# psoc4hvms128k register map
Vendor: Infineon Technologies; Series: PSOC4HVMS128K; File version: 1.0
CPU: CM0PLUS r0p1, little endian, MPU, no FPU, VTOR, 2 interrupt priority bits, 31 interrupts
Registers are 32-bit, read-write, reset 0x0 unless marked. A register's access mark holds for its fields unless they carry their own. Offsets are from the block's base; [hi:lo] are bit positions; {n}, {i} and the like mark numbered series; 'fields as' and 'values as' point back to an identical list; <NAME> marks a mode.

## SAR0 — SAR ADC with Sequencer
Base 0x403A0000
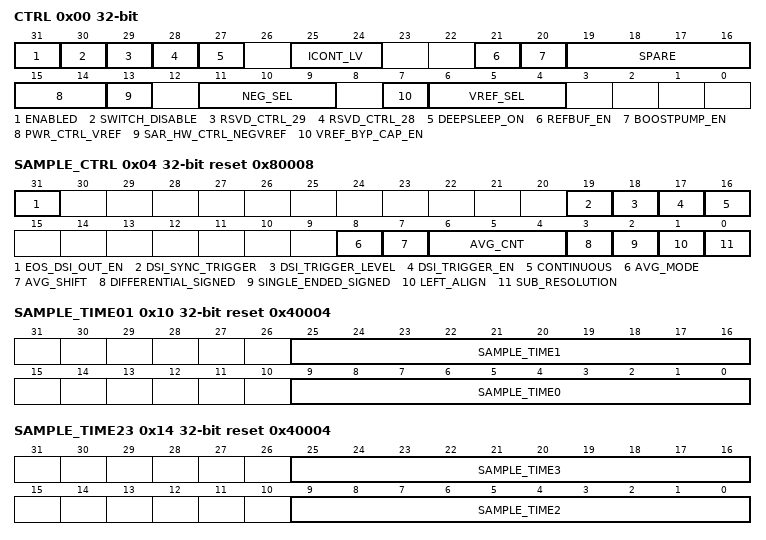
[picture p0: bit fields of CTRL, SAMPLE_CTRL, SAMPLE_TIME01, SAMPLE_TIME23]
0x00 CTRL — Analog control register.
  [31] ENABLED — - 0: SAR IP disabled (put analog in power down and stop clocks), also can clear FW_TRIGGER and INJ_START_EN (if not tailgaiting) on write. - 1: SAR IP enabled.
  [30] SWITCH_DISABLE — Disable SAR sequencer from enabling routing switches (note DSI and firmware can always close switches independent of this control) - 0: Normal mode, SAR sequencer changes switches according to pin address in channel configurations - 1: Switches disabled, SAR sequencer does not enable any switches, it is the responsibility of the firmware or UDBs (through DSI) to set the switches to route the signal to be converted through the SARMUX
  [29] RSVD_CTRL_29
  [28] RSVD_CTRL_28
  [27] DEEPSLEEP_ON — - 0: SARMUX IP disabled off during DeepSleep power mode - 1: SARMUX IP remains enabled during DeepSleep power mode (if ENABLED=1)
  [25:24] ICONT_LV — SARADC low power mode.
    0=NORMAL_PWR (normal power (default), max clk_sar is 18MHz.); 1=HALF_PWR (1/2 power mode, max clk_sar is 9MHz.); 2=MORE_PWR (1.333 power mode, max clk_sar is 18MHz.); 3=QUARTER_PWR (1/4 power mode, max clk_sar is 4.5MHz.)
  [21] REFBUF_EN — 1 - Enable the SARREFBUF. This bit needs to be set when SAR is enabled and needs reference buffer.
  [20] BOOSTPUMP_EN — SARADC internal pump: 0=disabled: pump output is VDDA, 1=enabled: pump output is boosted.
  [19:16] SPARE — Spare controls, not yet designated, for late changes done with an ECO
  [15:14] PWR_CTRL_VREF — VREF buffer low power mode.
    0=NORMAL_PWR (normal power (default), bypass cap, max clk_sar is 18MHz.); 1=HALF_PWR (deprecated); 2=THIRD_PWR (Invalid for PSoC4A, otherwise 2X power, no bypass cap, max clk_sar is 1.8MHz); 3=QUARTER_PWR (deprecated)
  [13] SAR_HW_CTRL_NEGVREF — Hardware control: 0=only firmware control, 1=hardware control masked by firmware setting for VREF to NEG switch.
  [11:9] NEG_SEL — SARADC internal NEG selection for Single ended conversion
    0=VSSA_KELVIN (NEG input of SARADC is connected to 'vssa_kelvin', gives more precision around zero. Note this opens both SARADC internal switches, therefore use this value to insert a break-before-make cycle on those switches when SWITCH_DISABLE is high.); 1=ART_VSSA (NEG input of SARADC is connected to VSSA in AROUTE close to the SARADC); 2=P1 (NEG input of SARADC is connected to P1 pin of SARMUX); 3=P3 (NEG input of SARADC is connected to P3 pin of SARMUX); 4=P5 (NEG input of SARADC is connected to P5 pin of SARMUX); 5=P7 (NEG input of SARADC is connected to P7 pin of SARMUX); 6=ACORE (NEG input of SARADC is connected to an ACORE in AROUTE); 7=VREF (NEG input of SARADC is shorted with VREF input of SARADC.)
  [7] VREF_BYP_CAP_EN — VREF bypass cap enable for when VREF buffer is on
  [6:4] VREF_SEL — SARADC internal VREF selection.
    0=RSVD_VREF_0 (N/A); 1=RSVD_VREF_1 (N/A); 2=RSVD_VREF_2 (N/A); 3=VREF_ADFT (Test mode only); 4=VBGR (1.2V from SRSS BandGap (VREF buffer on)); 5=VREF_EXT (External precision Vref direct from a pin (low impedance path).); 6=VDDA_DIV_2 (Vdda/2 (VREF buffer on)); 7=VDDA
0x04 SAMPLE_CTRL reset 0x80008 — Sample control register.
  [31] EOS_DSI_OUT_EN — Enable to output EOS_INTR to DSI. When enabled each time EOS_INTR is set by the hardware also a pulse is send on the dsi_eos signal.
  [19] DSI_SYNC_TRIGGER — - 0: bypass clock domain synchronisation of the DSI trigger signal. - 1: synchronize the DSI trigger signal to the SAR clock domain, if needed an edge detect is done in the peripheral clock domain.
  [18] DSI_TRIGGER_LEVEL — - 0: DSI trigger signal is a pulse input, a positive edge detected on the DSI trigger signal triggers a new scan. - 1: DSI trigger signal is a level input, as long as the DSI trigger signal remains high the SAR will do continuous scans.
  [17] DSI_TRIGGER_EN — - 0: firmware trigger only: disable hardware (DSI) trigger. - 1: enable hardware (DSI) trigger (e.g. from TCPWM, GPIO or UDB).
  [16] CONTINUOUS — - 0: Wait for next FW_TRIGGER (one shot) or hardware (DSI) trigger (e.g. from TPWM for periodic triggering) before scanning enabled channels. - 1: Continuously scan enabled channels, ignore triggers.
  [8] AVG_MODE — Averaging mode, in DSI mode this bit is ignored and only AccuNDump mode is available.
    0=ACCUNDUMP (Accumulate and Dump (1st order accumulate and dump filter): a channel will be sampled back to back and averaged); 1=INTERLEAVED (Interleaved: On each scan (trigger) one sample is taken per channel and averaged over several scans. NOTE: If all channels in a scan are configured for interleaved averaging, then EOS is only asserted after the last scan of the average count. In addition, a new trigger which would cause a collision, will be ignored, except for the last scan of the average count. If the collision is detected in the the last scan, the trigger will be pended and will be executed after the last scan is completed.)
  [7] AVG_SHIFT — Averaging shifting: after averaging the result is shifted right to fit in the sample resolution. For averaging the sample resolution is the highest resolution allowed by wounding.
  [6:4] AVG_CNT — Averaging Count for channels that have averaging enabled (AVG_EN). A channel will be sampled (1<<(AVG_CNT+1)) = [2..256] times. - In ACCUNDUMP mode (1st order accumulate and dump filter) a channel will be sampled back to back, the average result is calculated and stored and then the next enabled channel is sampled. If shifting is not enabled (AVG_SHIFT=0) then the result is forced to shift right so that is fits in 16 bits, so right shift is done by max(0,AVG_CNT-3). - In INTERLEAVED mode one sample is taken per triggered scan, only in the scan where the final averaging count is reached a valid average is calculated and stored in the RESULT register (by definition the same scan for all the channels that have averaging enabled). In all other scans the RESULT register for averaged channels will have an invalid result and the intermediate accumulated value is stored in the 16-bit WORK register. In this mode make sure that the averaging count is low enough to ensure that the intermediate value does not exceed 16-bits otherwise the MSBs will be lost. So for a 12-bit resolution the averaging count should be set to 16 or less (AVG_CNT=<3).
  [3] DIFFERENTIAL_SIGNED — Output data from a differential conversion as a signed value when DIFFERENTIAL_EN or NEG_ADDR_EN is set to 1 If AVG_MODE = 1 (Interleaved averaging), then DIFFERENTIAL_SIGNED must be configured identically to SINGLE_ENDED_SIGNED.
    0=UNSIGNED (result data is unsigned (zero extended if needed)); 1=SIGNED (Default: result data is signed (sign extended if needed))
  [2] SINGLE_ENDED_SIGNED — Output data from a single ended conversion as a signed value If AVG_MODE = 1 (Interleaved averaging), then SINGLE_ENDED_SIGNED must be configured identically to DIFFERENTIAL_SIGNED.
    0=UNSIGNED (Default: result data is unsigned (zero extended if needed)); 1=SIGNED (result data is signed (sign extended if needed))
  [1] LEFT_ALIGN — Left align data in data[15:0], default data is right aligned in data[11:0], with sign extension to 16 bits if the channel is differential.
  [0] SUB_RESOLUTION — Conversion resolution for channels that have sub-resolution enabled (RESOLUTION=1) (otherwise resolution is 12-bit).
    0=8B (8-bit.); 1=10B (10-bit.)
0x10 SAMPLE_TIME01 reset 0x40004 — Sample time specification ST0 and ST1
  [25:16] SAMPLE_TIME1
  [9:0] SAMPLE_TIME0 — Sample time0 (aperture) in ADC clock cycles. Note that actual sample time is half a clock less than specified here. The minimum sample time is 194ns, which is 3.5 cycles (4 in this field) with an 18MHz clock. Minimum legal value in this register is 2.
0x14 SAMPLE_TIME23 reset 0x40004 — Sample time specification ST2 and ST3
  [25:16] SAMPLE_TIME3, [9:0] SAMPLE_TIME2
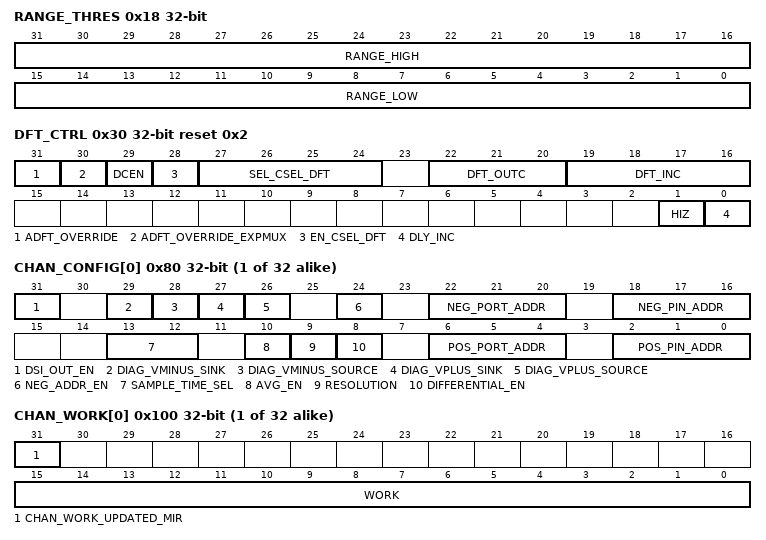
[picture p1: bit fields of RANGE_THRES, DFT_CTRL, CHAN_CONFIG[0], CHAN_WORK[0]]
0x18 RANGE_THRES — Global range detect threshold register.
  [31:16] RANGE_HIGH — High threshold for range detect.
  [15:0] RANGE_LOW — Low threshold for range detect.
0x1C RANGE_COND — Global range detect mode register.
  [31:30] RANGE_COND — Range condition select.
    0=BELOW (result < RANGE_LOW); 1=INSIDE (RANGE_LOW <= result < RANGE_HIGH); 2=ABOVE (RANGE_HIGH <= result); 3=OUTSIDE (result < RANGE_LOW || RANGE_HIGH <= result)
0x20 CHAN_EN — Enable bits for the channels
  [31:0] CHAN_EN — Channel enable. - 0: the corresponding channel is disabled. - 1: the corresponding channel is enabled, it will be included in the next scan.
0x24 START_CTRL — Start control register (firmware trigger).
  [0] FW_TRIGGER write-1-sets — When firmware writes a 1 here it will trigger the next scan of enabled channels, hardware clears this bit when the scan started with this trigger is completed. If scanning continuously the trigger is ignored and hardware clears this bit after the next scan is done. This bit is also cleared when the SAR is disabled.
0x30 DFT_CTRL reset 0x2 — DFT control register.
  [31] ADFT_OVERRIDE — During deepsleep/ hibernate mode keep SARMUX active, i.e. do not open all switches (disconnect), to be used for ADFT
  [30] ADFT_OVERRIDE_EXPMUX — During deepsleep/ hibernate mode keep EXPMUX active, i.e. do not open all switches (disconnect), to be used for ADFT.
  [29] DCEN — Delay Control Enable for latch. - 0: doubles the latch enable time. - 1: normal latch enable time.
  [28] EN_CSEL_DFT — Mux select signal for DAC control
  [27:24] SEL_CSEL_DFT — Usage 1: DFT bits for DAC array Usage 2: For [0]=1 (when dcen=0): Delay timing for latch enable increased by 20 percent [1]=1: comparator preamp power level increased by 25 percent
  [22:20] DFT_OUTC — DFT control for preamp outputs
  [19:16] DFT_INC — DFT control for preamp inputs
  [1] HIZ — DFT control for getting higher input impedance, must be 1 (0 is deprecated)
  [0] DLY_INC — DFT control: Control for delay circuits on sampling phase, =1 doubes the non-overlap delay
{0x80+4i} CHAN_CONFIG[{i}] (i=0..31) — Channel configuration register.
  [31] DSI_OUT_EN — DSI data output enable for this channel. - 0: the conversion result for this channel is only stored in the channel data register and the corresponding CHAN_DATA_VALID bit is set. - 1: the conversion result for this channel is stored in the channel data register and the corresponding CHAN_DATA_VALID bit is set. The same data (same formating), together with the channel number, is sent out on the DSI communication channel for processing in UDBs.
  [29] DIAG_VMINUS_SINK — Enable for 10uA current sink on vminus signal, active during sampling of this channel
  [28] DIAG_VMINUS_SOURCE — Enable for 10uA current source on vminus signal, active during sampling of this channel
  [27] DIAG_VPLUS_SINK — Enable for 10uA current sink on vplus signal, active during sampling of this channel
  [26] DIAG_VPLUS_SOURCE — Enable for 10uA current source on vplus signal, active during sampling of this channel
  [24] NEG_ADDR_EN — 1 - The NEG_PIN_ADDR and NEG_PORT_ADDR determines what drives the Vminus pin. This is a variation of differential mode with no even-odd pair limitation 0 - The NEG_SEL determines what drives the Vminus pin.
  [22:20] NEG_PORT_ADDR — Address of the neg port that contains the pin to be sampled by this channel.
    0=SARMUX (SARMUX pins.); 5=EXPMUX (GPIO Expansion Mux (if present)); 6=DIAGMUX (Diagnostic inputs); 7=SARMUX_VIRT (SARMUX virtual port (VPORT0))
  [18:16] NEG_PIN_ADDR — Address of the neg pin to be sampled by this channel.
  [13:12] SAMPLE_TIME_SEL — Sample time select: select which of the 4 global sample times to use for this channel
  [10] AVG_EN — Averaging enable for this channel. If set the AVG_CNT and AVG_SHIFT settings are used for sampling the addressed pin(s)
  [9] RESOLUTION — Resolution for this channel. When AVG_EN is set this bit is ignored and always a 12-bit resolution (or highest resolution allowed by wounding) is used for this channel.
    0=MAXRES (The maximum resolution is used for this channel (maximum resolution depends on wounding).); 1=SUBRES (The resolution specified by SUB_RESOLUTION in the SAR_SAMPLE_CTRL register is used for this channel.)
  [8] DIFFERENTIAL_EN — Legacy differential mode, usage is described by port below: SARMUX: Legacy mode, use applications should use NEG_PORT/PIN_ADDR CTB0-3: Special purpose, see CTB0 description EXPMUX: Legacy mode, use applications should use NEG_PORT/PIN_ADDR DIAGMUX: Not applicable SARMUX_VIRT: Special purpose, see SARMUX_VIRT description LEGACY MODE DESCRIPTION: Differential enable for the selected port pin for this channel. If differential is enabled then POS_PIN_ADDR[0] is ignored and considered to be 0, i.e. POS_PIN_ADDR points to the even pin of a pin pair. For differential the even pin of the pair is connected to Vplus and the odd pin of the pair is connected to Vminus. POS_PORT_ADDR is used to identify the port that contains the pins. - 0: The voltage on the addressed pin is measured (Single-ended) and the resulting value is stored in the corresponding data register. - 1: The differential voltage on the addressed pin pair is measured and the resulting value is stored in the corresponding data register. (POS_PIN_ADDR[0] is ignored). NOTE: Set to 0 if using the NEG_PIN_ADDR and NEG_PORT_ADDR to select the negative source.
  [6:4] POS_PORT_ADDR — Address of the port that contains the pin to be sampled by this channel (connected to Vplus)
    0=SARMUX (SARMUX PORT pins. Select POS_PIN_ADDR 0-7 for GPIO 0-7 See DIFF_EN bit description for legacy differential mode); 1=CTB0 (CTB0 Selet: POS_PIN_ADDR 2 for OA0 output (single ended)...); 2=CTB1 (CTB1 (see CTB0)); 3=CTB2 (CTB2 (see CTB0)); 4=CTB3 (CTB3 (see CTB0)); 5=EXPMUX (GPIO Expansion Mux (if present) See DIFF_EN bit description for legacy differential mode); 6=DIAGMUX (Diagnostic inputs); 7=SARMUX_VIRT (SARMUX virtual port (VPORT0) Select POS_PIN_ADDR 0 for Temp Sensor Select POS_PIN_ADDR 2 for AMUXBUSA (single ended, test only)...)
  [2:0] POS_PIN_ADDR — Address of the pin to be sampled by this channel (connected to Vplus)
{0x100+4i} CHAN_WORK[{i}] (i=0..31) ro (reset mask 0x80000000) — Channel working data register
  [31] CHAN_WORK_UPDATED_MIR — mirror bit of corresponding bit in SAR_CHAN_WORK_UPDATED register
  [15:0] WORK — SAR conversion working data of the channel. The data is written here right after sampling this channel.
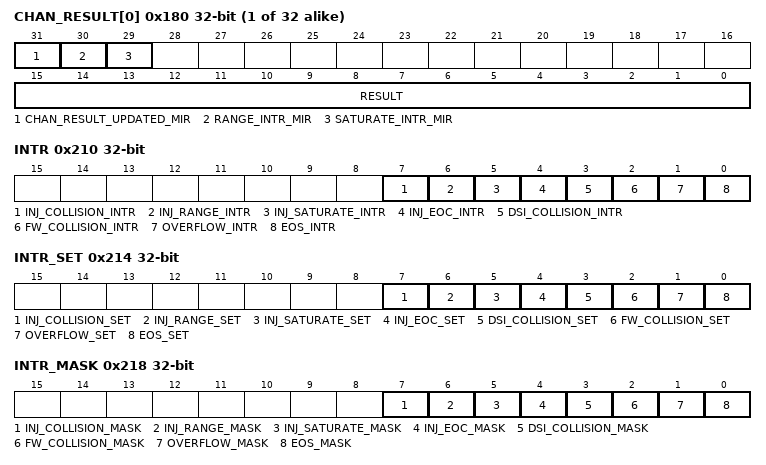
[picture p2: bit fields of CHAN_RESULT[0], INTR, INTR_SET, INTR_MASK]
{0x180+4i} CHAN_RESULT[{i}] (i=0..31) ro (reset mask 0xE0000000) — Channel result data register
  [31] CHAN_RESULT_UPDATED_MIR — mirror bit of corresponding bit in SAR_CHAN_RESULT_UPDATED register
  [30] RANGE_INTR_MIR — mirror bit of corresponding bit in SAR_RANGE_INTR register
  [29] SATURATE_INTR_MIR — mirror bit of corresponding bit in SAR_SATURATE_INTR register
  [15:0] RESULT — SAR conversion result of the channel. The data is copied here from the WORK field after all enabled channels in this scan have been sampled.
0x200 CHAN_WORK_UPDATED ro — Channel working data register 'updated' bits
  [31:0] CHAN_WORK_UPDATED — If set the corresponding WORK register was updated, i.e. was already sampled during the current scan and, in case of Interleaved averaging, reached the averaging count. If this bit is low then either the channel is not enabled or the averaging count is not yet reached for Interleaved averaging.
0x204 CHAN_RESULT_UPDATED ro — Channel result data register 'updated' bits
  [31:0] CHAN_RESULT_UPDATED — If set the corresponding RESULT register was updated, i.e. was sampled during the previous scan and, in case of Interleaved averaging, reached the averaging count. If this bit is low then either the channel is not enabled or the averaging count is not yet reached for Interleaved averaging.
0x210 INTR — Interrupt request register.
  [7] INJ_COLLISION_INTR write-1-clears — Injection Collision Interrupt: hardware sets this interrupt when the injection trigger signal is asserted (INJ_START_EN==1 && INJ_TAILGATING==0) while the SAR is BUSY. Raising this interrupt is delayed to when the sampling of the injection channel has been completed, i.e. not when the preceeding scan with which this trigger collided is completed. When this interrupt is set it implies that the injection channel was sampled later than was intended. Write with '1' to clear bit.
  [6] INJ_RANGE_INTR write-1-clears — Injection Range detect Interrupt: hardware sets this interrupt if the injection conversion result (after averaging) met the condition specified by the SAR_RANGE registers. Write with '1' to clear bit.
  [5] INJ_SATURATE_INTR write-1-clears — Injection Saturation Interrupt: hardware sets this interrupt if an injection conversion result (before averaging) is either 0x000 or 0xFFF (for 12-bit resolution), this is an indication that the ADC likely saturated. Write with '1' to clear bit.
  [4] INJ_EOC_INTR write-1-clears — Injection End of Conversion Interrupt: hardware sets this interrupt after completing the conversion for the injection channel (irrespective of if tailgating was used). Write with '1' to clear bit.
  [3] DSI_COLLISION_INTR write-1-clears — DSI Collision Interrupt: hardware sets this interrupt when the DSI trigger signal is asserted while the SAR is BUSY. Raising this interrupt is delayed to when the scan caused by the DSI trigger has been completed, i.e. not when the preceeding scan with which this trigger collided is completed. When this interrupt is set it implies that the channels were sampled later than was intended (jitter). Write with '1' to clear bit.
  [2] FW_COLLISION_INTR write-1-clears — Firmware Collision Interrupt: hardware sets this interrupt when FW_TRIGGER is asserted while the SAR is BUSY. Raising this interrupt is delayed to when the scan caused by the FW_TRIGGER has been completed, i.e. not when the preceeding scan with which this trigger collided is completed. When this interrupt is set it implies that the channels were sampled later than was intended (jitter). Write with '1' to clear bit.
  [1] OVERFLOW_INTR write-1-clears — Overflow Interrupt: hardware sets this interrupt when it sets a new EOS_INTR while that bit was not yet cleared by the firmware. Write with '1' to clear bit.
  [0] EOS_INTR write-1-clears — End Of Scan Interrupt: hardware sets this interrupt after completing a scan of all the enabled channels. Write with '1' to clear bit.
0x214 INTR_SET — Interrupt set request register
  [7] INJ_COLLISION_SET write-1-sets — Write with '1' to set corresponding bit in interrupt request register.
  [6] INJ_RANGE_SET write-1-sets — Write with '1' to set corresponding bit in interrupt request register.
  [5] INJ_SATURATE_SET write-1-sets — Write with '1' to set corresponding bit in interrupt request register.
  [4] INJ_EOC_SET write-1-sets — Write with '1' to set corresponding bit in interrupt request register.
  [3] DSI_COLLISION_SET write-1-sets — Write with '1' to set corresponding bit in interrupt request register.
  [2] FW_COLLISION_SET write-1-sets — Write with '1' to set corresponding bit in interrupt request register.
  [1] OVERFLOW_SET write-1-sets — Write with '1' to set corresponding bit in interrupt request register.
  [0] EOS_SET write-1-sets — Write with '1' to set corresponding bit in interrupt request register.
0x218 INTR_MASK — Interrupt mask register.
  [7] INJ_COLLISION_MASK — Mask bit for corresponding bit in interrupt request register.
  [6] INJ_RANGE_MASK — Mask bit for corresponding bit in interrupt request register.
  [5] INJ_SATURATE_MASK — Mask bit for corresponding bit in interrupt request register.
  [4] INJ_EOC_MASK — Mask bit for corresponding bit in interrupt request register.
  [3] DSI_COLLISION_MASK — Mask bit for corresponding bit in interrupt request register.
  [2] FW_COLLISION_MASK — Mask bit for corresponding bit in interrupt request register.
  [1] OVERFLOW_MASK — Mask bit for corresponding bit in interrupt request register.
  [0] EOS_MASK — Mask bit for corresponding bit in interrupt request register.
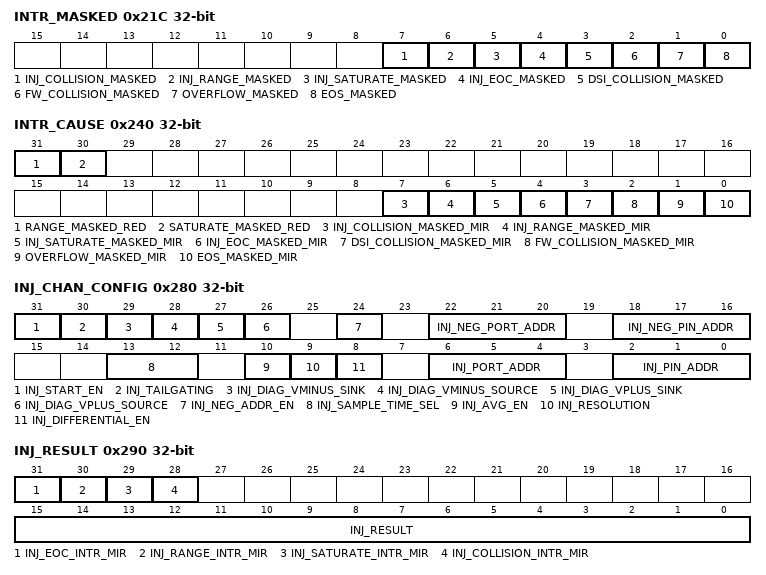
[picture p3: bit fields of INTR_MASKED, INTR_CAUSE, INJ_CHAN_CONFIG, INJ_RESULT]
0x21C INTR_MASKED ro — Interrupt masked request register
  [7] INJ_COLLISION_MASKED — Logical and of corresponding request and mask bits.
  [6] INJ_RANGE_MASKED — Logical and of corresponding request and mask bits.
  [5] INJ_SATURATE_MASKED — Logical and of corresponding request and mask bits.
  [4] INJ_EOC_MASKED — Logical and of corresponding request and mask bits.
  [3] DSI_COLLISION_MASKED — Logical and of corresponding request and mask bits.
  [2] FW_COLLISION_MASKED — Logical and of corresponding request and mask bits.
  [1] OVERFLOW_MASKED — Logical and of corresponding request and mask bits.
  [0] EOS_MASKED — Logical and of corresponding request and mask bits.
0x220 SATURATE_INTR — Saturate interrupt request register.
  [31:0] SATURATE_INTR write-1-clears — Saturate Interrupt: hardware sets this interrupt for each channel if a conversion result (before averaging) of that channel is either 0x000 or 0xFFF (for 12-bit resolution), this is an indication that the ADC likely saturated. Write with '1' to clear bit.
0x224 SATURATE_INTR_SET — Saturate interrupt set request register
  [31:0] SATURATE_SET write-1-sets — Write with '1' to set corresponding bit in interrupt request register.
0x228 SATURATE_INTR_MASK — Saturate interrupt mask register.
  [31:0] SATURATE_MASK — Mask bit for corresponding bit in interrupt request register.
0x22C SATURATE_INTR_MASKED ro — Saturate interrupt masked request register
  [31:0] SATURATE_MASKED — Logical and of corresponding request and mask bits.
0x230 RANGE_INTR — Range detect interrupt request register.
  [31:0] RANGE_INTR write-1-clears — Range detect Interrupt: hardware sets this interrupt for each channel if the conversion result (after averaging) of that channel met the condition specified by the SAR_RANGE registers. Write with '1' to clear bit.
0x234 RANGE_INTR_SET — Range detect interrupt set request register
  [31:0] RANGE_SET write-1-sets — Write with '1' to set corresponding bit in interrupt request register.
0x238 RANGE_INTR_MASK — Range detect interrupt mask register.
  [31:0] RANGE_MASK — Mask bit for corresponding bit in interrupt request register.
0x23C RANGE_INTR_MASKED ro — Range interrupt masked request register
  [31:0] RANGE_MASKED — Logical and of corresponding request and mask bits.
0x240 INTR_CAUSE ro — Interrupt cause register
  [31] RANGE_MASKED_RED — Reduction OR of all SAR_RANGE_INTR_MASKED bits
  [30] SATURATE_MASKED_RED — Reduction OR of all SAR_SATURATION_INTR_MASKED bits
  [7] INJ_COLLISION_MASKED_MIR — Mirror copy of corresponding bit in SAR_INTR_MASKED
  [6] INJ_RANGE_MASKED_MIR — Mirror copy of corresponding bit in SAR_INTR_MASKED
  [5] INJ_SATURATE_MASKED_MIR — Mirror copy of corresponding bit in SAR_INTR_MASKED
  [4] INJ_EOC_MASKED_MIR — Mirror copy of corresponding bit in SAR_INTR_MASKED
  [3] DSI_COLLISION_MASKED_MIR — Mirror copy of corresponding bit in SAR_INTR_MASKED
  [2] FW_COLLISION_MASKED_MIR — Mirror copy of corresponding bit in SAR_INTR_MASKED
  [1] OVERFLOW_MASKED_MIR — Mirror copy of corresponding bit in SAR_INTR_MASKED
  [0] EOS_MASKED_MIR — Mirror copy of corresponding bit in SAR_INTR_MASKED
0x280 INJ_CHAN_CONFIG — Injection channel configuration register.
  [31] INJ_START_EN write-1-sets — Set by firmware to enable the injection channel. If INJ_TAILGATING is not set this bit also functions as trigger for this channel. Cleared by hardware after this channel has been sampled (i.e. this channel is always one shot even if CONTINUOUS is set). Also cleared if the SAR is disabled. NOTE: If the intent is to trigger an injection channel with no tailgaiting (immediately if not busy), just prior to a firmware trigger, the following sequence must be followed to ensure that the injection channel starts first: - Trigger injection channel (set this bit to 1) - Poll for busy (wait for STATUS.SAR_BUSY == 1) - Trigger the scan (START_CTRL.FW_TRIGGER set to 1)
  [30] INJ_TAILGATING — Injection channel tailgating. - 0: no tailgating for this channel, SAR is immediately triggered when the INJ_START_EN bit is set if the SAR is not busy. If the SAR is busy, the INJ channel addressed pin is sampled at the end of the current scan. - 1: injection channel tailgating. The addressed pin is sampled after the next trigger and after all enabled channels have been scanned.
  [29] INJ_DIAG_VMINUS_SINK — Enable for 10uA current sink on vminus signal, active during sampling of this channel
  [28] INJ_DIAG_VMINUS_SOURCE — Enable for 10uA current source on vminus signal, active during sampling of this channel
  [27] INJ_DIAG_VPLUS_SINK — Enable for 10uA current sink on vplus signal, active during sampling of this channel
  [26] INJ_DIAG_VPLUS_SOURCE — Enable for 10uA current source on vplus signal, active during sampling of this channel
  [24] INJ_NEG_ADDR_EN — 1 - The NEG_PIN_ADDR and NEG_PORT_ADDR determines what drives the Vminus pin. This is a variation of differential mode with no even-odd pair limitation 0 - The NEG_SEL determines what drives the Vminus pin. DIFFERENTIAL_EN must be set to 0 for this feature to work correctly.
  [22:20] INJ_NEG_PORT_ADDR — Address of the neg port that contains the pin to be sampled by the injection channel.
    values as CHAN_CONFIG[0].NEG_PORT_ADDR
  [18:16] INJ_NEG_PIN_ADDR — Address of the neg pin to be sampled by the injection channel.
  [13:12] INJ_SAMPLE_TIME_SEL — Injection sample time select: select which of the 4 global sample times to use for this channel
  [10] INJ_AVG_EN — Averaging enable for this channel. If set the AVG_CNT and AVG_SHIFT settings are used for sampling the addressed pin(s)
  [9] INJ_RESOLUTION — Resolution for this channel.
    0=12B (12-bit resolution is used for this channel.); 1=SUBRES (The resolution specified by SUB_RESOLUTION in the SAR_SAMPLE_CTRL register is used for this channel.)
  [8] INJ_DIFFERENTIAL_EN — Legacy differential mode, usage is described by port below: SARMUX: Legacy mode, use applications should use NEG_PORT/PIN_ADDR CTB0-3: Special purpose, see CTB0 description EXPMUX: Legacy mode, use applications should use NEG_PORT/PIN_ADDR DIAGMUX: Not applicable SARMUX_VIRT: Special purpose, see SARMUX_VIRT description LEGACY MODE DESCRIPTION: Differential enable for the selected port pin for this channel. If differential is enabled then POS_PIN_ADDR[0] is ignored and considered to be 0, i.e. POS_PIN_ADDR points to the even pin of a pin pair. For differential the even pin of the pair is connected to Vplus and the odd pin of the pair is connected to Vminus. POS_PORT_ADDR is used to identify the port that contains the pins. - 0: The voltage on the addressed pin is measured (Single-ended) and the resulting value is stored in the corresponding data register. - 1: The differential voltage on the addressed pin pair is measured and the resulting value is stored in the corresponding data register. (POS_PIN_ADDR[0] is ignored). NOTE: Set to 0 if using the NEG_PIN_ADDR and NEG_PORT_ADDR to select the negative source.
  [6:4] INJ_PORT_ADDR — Address of the port that contains the pin to be sampled by this channel (connected to Vplus)
    values as CHAN_CONFIG[0].POS_PORT_ADDR
  [2:0] INJ_PIN_ADDR — Address of the pin to be sampled by this injection channel. If differential is enabled then INJ_PIN_ADDR[0] is ignored and considered to be 0, i.e. INJ_PIN_ADDR points to the even pin of a pin pair.
0x290 INJ_RESULT ro (reset mask 0xF0000000) — Injection channel result register
  [31] INJ_EOC_INTR_MIR — mirror bit of corresponding bit in SAR_INTR register
  [30] INJ_RANGE_INTR_MIR — mirror bit of corresponding bit in SAR_INTR register
  [29] INJ_SATURATE_INTR_MIR — mirror bit of corresponding bit in SAR_INTR register
  [28] INJ_COLLISION_INTR_MIR — mirror bit of corresponding bit in SAR_INTR register
  [15:0] INJ_RESULT — SAR conversion result of the channel.
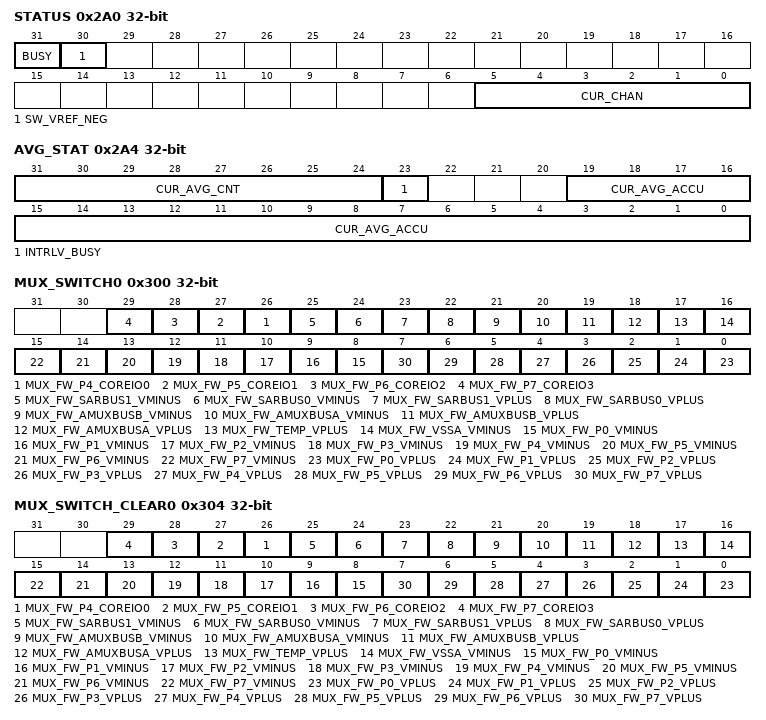
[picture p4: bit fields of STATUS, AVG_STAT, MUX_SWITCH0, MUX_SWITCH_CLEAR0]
0x2A0 STATUS ro — Current status of internal SAR registers (mostly for debug)
  [31] BUSY — If high then the SAR is busy with a conversion. This bit is always high when CONTINUOUS is set. Firmware should wait for this bit to be low before putting the SAR in power down.
  [30] SW_VREF_NEG — the current switch status, including DSI and sequencer controls, of the switch in the SARADC that shorts NEG with VREF input (see NEG_SEL).
  [5:0] CUR_CHAN — current channel being sampled (channel 16 indicates the injection channel), only valid if BUSY.
0x2A4 AVG_STAT ro — Current averaging status (for debug)
  [31:24] CUR_AVG_CNT — the current value of the averaging counter. Note that the value shown is updated after the sampling time and therefore runs ahead of the accumulator update.
  [23] INTRLV_BUSY — If high then the SAR is in the middle of Interleaved averaging spanning several scans. While this bit is high the Firmware should not make any changes to the configuration registers otherwise some results may be incorrect. Note that the CUR_AVG_CNT status register below gives an indication how many more scans need to be done to complete the Interleaved averaging. This bit can be cleared by changing the averaging mode to ACCUNDUMP or by disabling the SAR.
  [19:0] CUR_AVG_ACCU — the current value of the averaging accumulator
0x300 MUX_SWITCH0 — SARMUX Firmware switch controls
  [n+22] MUX_FW_P{n}_COREIO{n-4} write-1-sets (n=4..7) — Firmware control: 0=open, 1=close switch between P{n} and coreio{n-4} signal. Write with '1' to set bit.
  [25] MUX_FW_SARBUS1_VMINUS write-1-sets — Firmware control: 0=open, 1=close switch between sarbus1 and vminus signal. Write with '1' to set bit.
  [24] MUX_FW_SARBUS0_VMINUS write-1-sets — Firmware control: 0=open, 1=close switch between sarbus0 and vminus signal. Write with '1' to set bit.
  [23] MUX_FW_SARBUS1_VPLUS write-1-sets — Firmware control: 0=open, 1=close switch between sarbus1 and vplus signal. Write with '1' to set bit.
  [22] MUX_FW_SARBUS0_VPLUS write-1-sets — Firmware control: 0=open, 1=close switch between sarbus0 and vplus signal. Write with '1' to set bit.
  [21] MUX_FW_AMUXBUSB_VMINUS write-1-sets — Firmware control: 0=open, 1=close switch between amuxbusb and vminus signal. Write with '1' to set bit.
  [20] MUX_FW_AMUXBUSA_VMINUS write-1-sets — Firmware control: 0=open, 1=close switch between amuxbusa and vminus signal. Write with '1' to set bit.
  [19] MUX_FW_AMUXBUSB_VPLUS write-1-sets — Firmware control: 0=open, 1=close switch between amuxbusb and vplus signal. Write with '1' to set bit.
  [18] MUX_FW_AMUXBUSA_VPLUS write-1-sets — Firmware control: 0=open, 1=close switch between amuxbusa and vplus signal. Write with '1' to set bit.
  [17] MUX_FW_TEMP_VPLUS write-1-sets — Firmware control: 0=open, 1=close switch between temperature sensor and vplus signal, also powers on the temperature sensor. Write with '1' to set bit.
  [16] MUX_FW_VSSA_VMINUS write-1-sets — Firmware control: 0=open, 1=close switch between vssa_kelvin and vminus signal. Write with '1' to set bit.
  [n+8] MUX_FW_P{n}_VMINUS write-1-sets (n=0..7) — Firmware control: 0=open, 1=close switch between pin P{n} and vminus signal. Write with '1' to set bit.
  [n] MUX_FW_P{n}_VPLUS write-1-sets (n=0..7) — Firmware control: 0=open, 1=close switch between pin P{n} and vplus signal. Write with '1' to set bit.
0x304 MUX_SWITCH_CLEAR0 — SARMUX Firmware switch control clear
  [n+22] MUX_FW_P{n}_COREIO{n-4} write-1-clears (n=4..7) — Write '1' to clear corresponding bit in MUX_SWITCH0
  [25] MUX_FW_SARBUS1_VMINUS write-1-clears — Write '1' to clear corresponding bit in MUX_SWITCH0
  [24] MUX_FW_SARBUS0_VMINUS write-1-clears — Write '1' to clear corresponding bit in MUX_SWITCH0
  [23] MUX_FW_SARBUS1_VPLUS write-1-clears — Write '1' to clear corresponding bit in MUX_SWITCH0
  [22] MUX_FW_SARBUS0_VPLUS write-1-clears — Write '1' to clear corresponding bit in MUX_SWITCH0
  [21] MUX_FW_AMUXBUSB_VMINUS write-1-clears — Write '1' to clear corresponding bit in MUX_SWITCH0
  [20] MUX_FW_AMUXBUSA_VMINUS write-1-clears — Write '1' to clear corresponding bit in MUX_SWITCH0
  [19] MUX_FW_AMUXBUSB_VPLUS write-1-clears — Write '1' to clear corresponding bit in MUX_SWITCH0
  [18] MUX_FW_AMUXBUSA_VPLUS write-1-clears — Write '1' to clear corresponding bit in MUX_SWITCH0
  [17] MUX_FW_TEMP_VPLUS write-1-clears — Write '1' to clear corresponding bit in MUX_SWITCH0
  [16] MUX_FW_VSSA_VMINUS write-1-clears — Write '1' to clear corresponding bit in MUX_SWITCH0
  [n+8] MUX_FW_P{n}_VMINUS write-1-clears (n=0..7) — Write '1' to clear corresponding bit in MUX_SWITCH0
  [n] MUX_FW_P{n}_VPLUS write-1-clears (n=0..7) — Write '1' to clear corresponding bit in MUX_SWITCH0
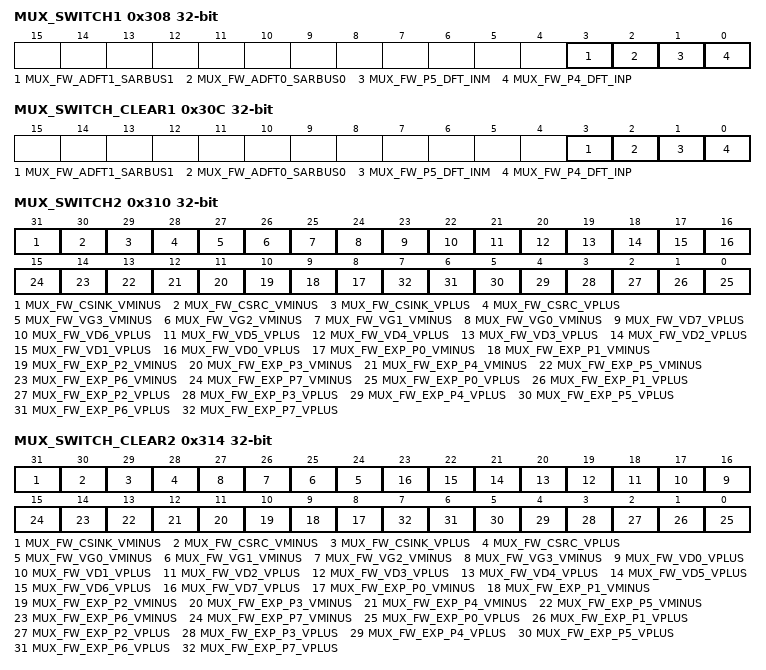
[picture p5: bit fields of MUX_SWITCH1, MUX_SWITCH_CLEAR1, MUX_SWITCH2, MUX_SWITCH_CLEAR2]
0x308 MUX_SWITCH1 — SARMUX Firmware switch controls
  [3] MUX_FW_ADFT1_SARBUS1 write-1-sets — Firmware control: 0=open, 1=close switch between adft1 signal and sarbus1 signal. Write with '1' to set bit.
  [2] MUX_FW_ADFT0_SARBUS0 write-1-sets — Firmware control: 0=open, 1=close switch between adft0 signal and sarbus0 signal. Write with '1' to set bit.
  [1] MUX_FW_P5_DFT_INM write-1-sets — Firmware control: 0=open, 1=close switch between P5 pin and dft_inm signal. Write with '1' to set bit.
  [0] MUX_FW_P4_DFT_INP write-1-sets — Firmware control: 0=open, 1=close switch between P4 pin and dft_inp signal. Write with '1' to set bit.
0x30C MUX_SWITCH_CLEAR1 — SARMUX Firmware switch control clear
  [3] MUX_FW_ADFT1_SARBUS1 write-1-clears — Write '1' to clear corresponding bit in MUX_SWITCH1
  [2] MUX_FW_ADFT0_SARBUS0 write-1-clears — Write '1' to clear corresponding bit in MUX_SWITCH1
  [1] MUX_FW_P5_DFT_INM write-1-clears — Write '1' to clear corresponding bit in MUX_SWITCH1
  [0] MUX_FW_P4_DFT_INP write-1-clears — Write '1' to clear corresponding bit in MUX_SWITCH1
0x310 MUX_SWITCH2 — EXPMUX and DIAGMUX Firmware switch controls
  [31] MUX_FW_CSINK_VMINUS write-1-sets — Firmware control: 0=open, 1=close switch between 10uA current sink and the vminus signal Write with '1' to set bit.
  [30] MUX_FW_CSRC_VMINUS write-1-sets — Firmware control: 0=open, 1=close switch between 10uA current source and the vplus signal Write with '1' to set bit.
  [29] MUX_FW_CSINK_VPLUS write-1-sets — Firmware control: 0=open, 1=close switch between 10uA current sink and the vplus signal Write with '1' to set bit.
  [28] MUX_FW_CSRC_VPLUS write-1-sets — Firmware control: 0=open, 1=close switch between 10uA current source and the vplus signal Write with '1' to set bit.
  [27] MUX_FW_VG3_VMINUS write-1-sets — Firmware control: 0=open, 1=close switch between internal Vgnd.3 and vplus signal . Write with '1' to set bit.
  [26] MUX_FW_VG2_VMINUS write-1-sets — Firmware control: 0=open, 1=close switch between internal Vgnd.2 and vplus signal . Write with '1' to set bit.
  [25] MUX_FW_VG1_VMINUS write-1-sets — Firmware control: 0=open, 1=close switch between internal Vgnd.1 and vplus signal . Write with '1' to set bit.
  [24] MUX_FW_VG0_VMINUS write-1-sets — Firmware control: 0=open, 1=close switch between internal Vgnd.0 and vplus signal . Write with '1' to set bit.
  [23] MUX_FW_VD7_VPLUS write-1-sets — Firmware control: 0=open, 1=close switch between internal Vdiag.7 and vplus signal . Write with '1' to set bit.
  [22] MUX_FW_VD6_VPLUS write-1-sets — Firmware control: 0=open, 1=close switch between internal Vdiag.6 and vplus signal . Write with '1' to set bit.
  [21] MUX_FW_VD5_VPLUS write-1-sets — Firmware control: 0=open, 1=close switch between internal Vdiag.5 and vplus signal . Write with '1' to set bit.
  [20] MUX_FW_VD4_VPLUS write-1-sets — Firmware control: 0=open, 1=close switch between internal Vdiag.4 and vplus signal . Write with '1' to set bit.
  [19] MUX_FW_VD3_VPLUS write-1-sets — Firmware control: 0=open, 1=close switch between internal Vdiag.3 and vplus signal . Write with '1' to set bit.
  [18] MUX_FW_VD2_VPLUS write-1-sets — Firmware control: 0=open, 1=close switch between internal Vdiag.2 and vplus signal . Write with '1' to set bit.
  [17] MUX_FW_VD1_VPLUS write-1-sets — Firmware control: 0=open, 1=close switch between internal Vdiag.1 and vplus signal . Write with '1' to set bit.
  [16] MUX_FW_VD0_VPLUS write-1-sets — Firmware control: 0=open, 1=close switch between internal Vdiag.0 and vplus signal . Write with '1' to set bit.
  [n+8] MUX_FW_EXP_P{n}_VMINUS write-1-sets (n=0..7) — Firmware control: 0=open, 1=close switch between pin P{n} and vminus signal. Write with '1' to set bit.
  [n] MUX_FW_EXP_P{n}_VPLUS write-1-sets (n=0..7) — Firmware control: 0=open, 1=close switch between pin P{n} and vplus signal. Write with '1' to set bit.
0x314 MUX_SWITCH_CLEAR2 — EXPMUX and DIAGMUX Firmware switch control clear
  [31] MUX_FW_CSINK_VMINUS write-1-clears — Write '1' to clear corresponding bit in MUX_SWITCH2
  [30] MUX_FW_CSRC_VMINUS write-1-clears — Write '1' to clear corresponding bit in MUX_SWITCH2
  [29] MUX_FW_CSINK_VPLUS write-1-clears — Write '1' to clear corresponding bit in MUX_SWITCH2
  [28] MUX_FW_CSRC_VPLUS write-1-clears — Write '1' to clear corresponding bit in MUX_SWITCH2
  [n+24] MUX_FW_VG{n}_VMINUS write-1-clears (n=0..3) — Write '1' to clear corresponding bit in MUX_SWITCH2
  [n+16] MUX_FW_VD{n}_VPLUS write-1-clears (n=0..7) — Write '1' to clear corresponding bit in MUX_SWITCH2
  [n+8] MUX_FW_EXP_P{n}_VMINUS write-1-clears (n=0..7) — Write '1' to clear corresponding bit in MUX_SWITCH2
  [n] MUX_FW_EXP_P{n}_VPLUS write-1-clears (n=0..7) — Write '1' to clear corresponding bit in MUX_SWITCH2
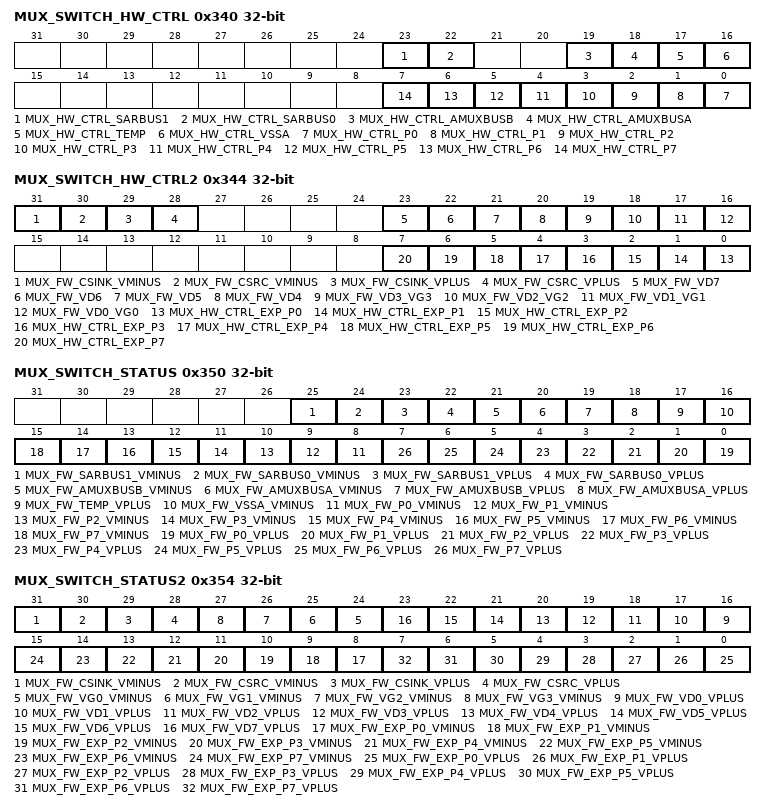
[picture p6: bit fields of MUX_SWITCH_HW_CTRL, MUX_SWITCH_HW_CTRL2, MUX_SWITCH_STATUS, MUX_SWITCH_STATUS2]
0x340 MUX_SWITCH_HW_CTRL — SARMUX switch hardware control
  [23] MUX_HW_CTRL_SARBUS1 — Hardware control: 0=only firmware control, 1=hardware control masked by firmware setting for sarbus1 switches.
  [22] MUX_HW_CTRL_SARBUS0 — Hardware control: 0=only firmware control, 1=hardware control masked by firmware setting for sarbus0 switches.
  [19] MUX_HW_CTRL_AMUXBUSB — Hardware control: 0=only firmware control, 1=hardware control masked by firmware setting for amuxbusb switches.
  [18] MUX_HW_CTRL_AMUXBUSA — Hardware control: 0=only firmware control, 1=hardware control masked by firmware setting for amuxbusa switches.
  [17] MUX_HW_CTRL_TEMP — Hardware control: 0=only firmware control, 1=hardware control masked by firmware setting for temp switch.
  [16] MUX_HW_CTRL_VSSA — Hardware control: 0=only firmware control, 1=hardware control masked by firmware setting for vssa switch.
  [n] MUX_HW_CTRL_P{n} (n=0..7) — Hardware control: 0=only firmware control, 1=hardware control masked by firmware setting for pin P{n} switches.
0x344 MUX_SWITCH_HW_CTRL2 — EXPMUX and DIAGMUX switch hardware control
  [31] MUX_FW_CSINK_VMINUS — Hardware control: 0=only firmware control, 1=hardware control masked by firmware setting to close switch between 10uA current sink and the vminus signal.
  [30] MUX_FW_CSRC_VMINUS — Hardware control: 0=only firmware control, 1=hardware control masked by firmware setting for close switch between 10uA current source and the vminus signal.
  [29] MUX_FW_CSINK_VPLUS — Hardware control: 0=only firmware control, 1=hardware control masked by firmware setting for close switch between 10uA current sink and the vplus signal.
  [28] MUX_FW_CSRC_VPLUS — Hardware control: 0=only firmware control, 1=hardware control masked by firmware setting to close switch between 10uA current source and the vplus signal.
  [23] MUX_FW_VD7 — Hardware control: 0=only firmware control, 1=hardware control masked by firmware setting for Vdiag.7 switch.
  [22] MUX_FW_VD6 — Hardware control: 0=only firmware control, 1=hardware control masked by firmware setting for Vdiag.6 switch.
  [21] MUX_FW_VD5 — Hardware control: 0=only firmware control, 1=hardware control masked by firmware setting for Vdiag.5 switch.
  [20] MUX_FW_VD4 — Hardware control: 0=only firmware control, 1=hardware control masked by firmware setting for Vdiag.4 switch.
  [19] MUX_FW_VD3_VG3 — Hardware control: 0=only firmware control, 1=hardware control masked by firmware setting for Vdiag.3 and Vgnd.3 switches
  [18] MUX_FW_VD2_VG2 — Hardware control: 0=only firmware control, 1=hardware control masked by firmware setting for Vdiag.2 and Vgnd.2 switches
  [17] MUX_FW_VD1_VG1 — Hardware control: 0=only firmware control, 1=hardware control masked by firmware setting for Vdiag.1 and Vgnd.1 switches
  [16] MUX_FW_VD0_VG0 — Hardware control: 0=only firmware control, 1=hardware control masked by firmware setting for Vdiag.0 and Vgnd.0 switches
  [n] MUX_HW_CTRL_EXP_P{n} (n=0..7) — Hardware control: 0=only firmware control, 1=hardware control masked by firmware setting for pin P{n} switches.
0x350 MUX_SWITCH_STATUS ro — SARMUX switch status
  [25] MUX_FW_SARBUS1_VMINUS — switch status of corresponding bit in MUX_SWITCH0
  [24] MUX_FW_SARBUS0_VMINUS — switch status of corresponding bit in MUX_SWITCH0
  [23] MUX_FW_SARBUS1_VPLUS — switch status of corresponding bit in MUX_SWITCH0
  [22] MUX_FW_SARBUS0_VPLUS — switch status of corresponding bit in MUX_SWITCH0
  [21] MUX_FW_AMUXBUSB_VMINUS — switch status of corresponding bit in MUX_SWITCH0
  [20] MUX_FW_AMUXBUSA_VMINUS — switch status of corresponding bit in MUX_SWITCH0
  [19] MUX_FW_AMUXBUSB_VPLUS — switch status of corresponding bit in MUX_SWITCH0
  [18] MUX_FW_AMUXBUSA_VPLUS — switch status of corresponding bit in MUX_SWITCH0
  [17] MUX_FW_TEMP_VPLUS — switch status of corresponding bit in MUX_SWITCH0
  [16] MUX_FW_VSSA_VMINUS — switch status of corresponding bit in MUX_SWITCH0
  [n+8] MUX_FW_P{n}_VMINUS (n=0..7) — switch status of corresponding bit in MUX_SWITCH0
  [n] MUX_FW_P{n}_VPLUS (n=0..7) — switch status of corresponding bit in MUX_SWITCH0
0x354 MUX_SWITCH_STATUS2 ro — EXPMUX and DIAGMUX switch status
  [31] MUX_FW_CSINK_VMINUS — switch status of corresponding bit in MUX_SWITCH2
  [30] MUX_FW_CSRC_VMINUS — switch status of corresponding bit in MUX_SWITCH2
  [29] MUX_FW_CSINK_VPLUS — switch status of corresponding bit in MUX_SWITCH2
  [28] MUX_FW_CSRC_VPLUS — switch status of corresponding bit in MUX_SWITCH2
  [n+24] MUX_FW_VG{n}_VMINUS (n=0..3) — switch status of corresponding bit in MUX_SWITCH2
  [n+16] MUX_FW_VD{n}_VPLUS (n=0..7) — switch status of corresponding bit in MUX_SWITCH2
  [n+8] MUX_FW_EXP_P{n}_VMINUS (n=0..7) — switch status of corresponding bit in MUX_SWITCH2
  [n] MUX_FW_EXP_P{n}_VPLUS (n=0..7) — switch status of corresponding bit in MUX_SWITCH2
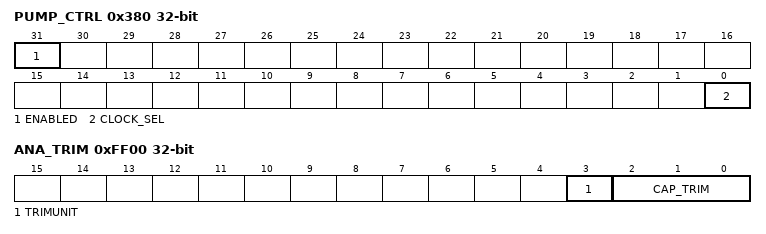
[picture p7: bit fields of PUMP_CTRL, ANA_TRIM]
0x380 PUMP_CTRL — Switch pump control
  [31] ENABLED — 0=disabled: pump output is VDDA_PUMP, 1=enabled: pump output is boosted.
  [0] CLOCK_SEL — Clock select: 0=external clock, 1=internal clock (deprecated).
0xFF00 ANA_TRIM — Analog trim register.
  [3] TRIMUNIT — Attenuation cap trimming
  [2:0] CAP_TRIM — Attenuation cap trimming
0xFF04 WOUNDING — SAR wounding register
  [1:0] WOUND_RESOLUTION write-1-sets — Maximum SAR resolution allowed
    0=12BIT (unwounded: up to full 12-bit SAR resolution allowed); 1=10BIT (wounded: max resolution upto 10-bit SAR resolution allowed); 2=8BIT (wounded: only 8-bit SAR resolution allowed); 3=8BIT_TOO (wounded: only 8-bit SAR resolution allowed)
